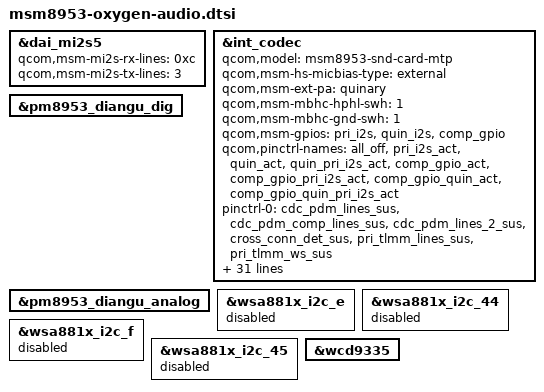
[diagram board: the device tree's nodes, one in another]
/*
 * Copyright (c) 2015-2018, The Linux Foundation. All rights reserved.
 *
 * This program is free software; you can redistribute it and/or modify
 * it under the terms of the GNU General Public License version 2 and
 * only version 2 as published by the Free Software Foundation.
 *
 * This program is distributed in the hope that it will be useful,
 * but WITHOUT ANY WARRANTY; without even the implied warranty of
 * MERCHANTABILITY or FITNESS FOR A PARTICULAR PURPOSE.  See the
 * GNU General Public License for more details.
 */

&dai_mi2s5 {
	qcom,msm-mi2s-rx-lines = <0xc>;
	qcom,msm-mi2s-tx-lines = <3>;
};

&int_codec {
	status = "okay";
	qcom,model = "msm8953-snd-card-mtp";
	qcom,msm-hs-micbias-type = "external";
	qcom,msm-ext-pa = "quinary";
	/delete-property/ qcom,hdmi-dba-codec-rx;
	/delete-property/ qcom,cdc-us-euro-gpios;

	qcom,msm-mbhc-hphl-swh = <1>;
	qcom,msm-mbhc-gnd-swh = <1>;

	qcom,msm-gpios =
		"pri_i2s",
		"quin_i2s",
		"comp_gpio";
	qcom,pinctrl-names =
		"all_off",
		"pri_i2s_act",
		"quin_act",
		"quin_pri_i2s_act",
		"comp_gpio_act",
		"comp_gpio_pri_i2s_act",
		"comp_gpio_quin_act",
		"comp_gpio_quin_pri_i2s_act";

	pinctrl-names =
		"all_off",
		"pri_i2s_act",
		"quin_act",
		"quin_pri_i2s_act",
		"comp_gpio_act",
		"comp_gpio_pri_i2s_act",
		"comp_gpio_quin_act",
		"comp_gpio_quin_pri_i2s_act";

	pinctrl-0 = <&cdc_pdm_lines_sus &cdc_pdm_comp_lines_sus
		&cdc_pdm_lines_2_sus &cross_conn_det_sus
		&pri_tlmm_lines_sus &pri_tlmm_ws_sus>;
	pinctrl-1 = <&cdc_pdm_lines_act &cdc_pdm_comp_lines_sus
		&cdc_pdm_lines_2_act &cross_conn_det_sus
		&pri_tlmm_lines_sus &pri_tlmm_ws_sus>;
	pinctrl-2 = <&cdc_pdm_lines_sus &cdc_pdm_comp_lines_sus
		&cdc_pdm_lines_2_sus &cross_conn_det_sus
		&pri_tlmm_lines_act &pri_tlmm_ws_act>;
	pinctrl-3 = <&cdc_pdm_lines_act &cdc_pdm_comp_lines_sus
		&cdc_pdm_lines_2_act &cross_conn_det_sus
		&pri_tlmm_lines_act &pri_tlmm_ws_act>;
	pinctrl-4 = <&cdc_pdm_lines_sus &cdc_pdm_comp_lines_act
		&cdc_pdm_lines_2_sus &cross_conn_det_sus
		&pri_tlmm_lines_sus &pri_tlmm_ws_sus>;
	pinctrl-5 = <&cdc_pdm_lines_act &cdc_pdm_comp_lines_act
		&cdc_pdm_lines_2_act &cross_conn_det_sus
		&pri_tlmm_lines_sus &pri_tlmm_ws_sus>;
	pinctrl-6 = <&cdc_pdm_lines_sus &cdc_pdm_comp_lines_act
		&cdc_pdm_lines_2_sus &cross_conn_det_sus
		&pri_tlmm_lines_act &pri_tlmm_ws_act>;
	pinctrl-7 = <&cdc_pdm_lines_act &cdc_pdm_comp_lines_act
		&cdc_pdm_lines_2_act &cross_conn_det_sus
		&pri_tlmm_lines_act &pri_tlmm_ws_act>;

	asoc-codec = <&stub_codec>, <&pm8953_diangu_dig>;
	asoc-codec-names = "msm-stub-codec.1", "cajon_codec";

	/delete-property/ pinctrl-8;
	/delete-property/ pinctrl-9;
	/delete-property/ pinctrl-10;
	/delete-property/ pinctrl-11;
	/delete-property/ pinctrl-12;
	/delete-property/ pinctrl-13;
	/delete-property/ pinctrl-14;
	/delete-property/ pinctrl-15;

	/delete-property/ asoc-wsa-codec-names;
	/delete-property/ asoc-wsa-codec-prefixes;

	/delete-property/ msm-vdd-wsa-switch-supply;
	/delete-property/ qcom,msm-vdd-wsa-switch-voltage;
	/delete-property/ qcom,msm-vdd-wsa-switch-current;
};

&pm8953_diangu_dig {
	status = "okay";
};

&pm8953_diangu_analog {
	status = "okay";
};

&wsa881x_i2c_e {
	status = "disabled";
};

&wsa881x_i2c_44 {
	status = "disabled";
};

&wsa881x_i2c_f {
	status = "disabled";
};

&wsa881x_i2c_45 {
	status = "disabled";
};

&wcd9335 {
	/delete-property/ cdc-vdd-buck-supply;
	/delete-property/ cdc-buck-sido-supply;
	/delete-property/ cdc-vdd-tx-h-supply;
	/delete-property/ cdc-vdd-rx-h-supply;
	/delete-property/ cdc-vdd-px-supply;
};
